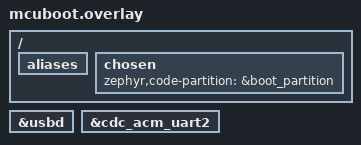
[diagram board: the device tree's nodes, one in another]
/*
 * Copyright (c) 2026 zlrs contributors
 *
 * SPDX-License-Identifier: Apache-2.0
 *
 * Devicetree overlay for the mcuboot image only (sysbuild picks up app/sysbuild/<image>.overlay).
 *
 * The application has data and management CDCs; the bootloader keeps two:
 *   - cdc_acm_uart0 = data port -> serial recovery (mcumgr frames; `zephyr,uart-mcumgr`
 *     points at it in the board dts)
 *   - cdc_acm_uart2 = console -> kernel log (disabled by default, enabled here)
 *   - cdc_acm_uart1 (management) is deleted in the bootloader
 * In upgrade mode the host then sees two MCUBOOT ports: recovery first, log second.
 *
 * This overlay also has to set `zephyr,code-partition = &boot_partition` itself: Zephyr only
 * falls back to MCUboot's own bootloader/mcuboot/boot/zephyr/app.overlay when there is *no*
 * DTC_OVERLAY_FILE, and that file holds this single line (the bootloader must link against the
 * mcuboot partition at 0x0, not slot0). Bring it along when providing your own overlay.
 */

/ {
	aliases {
		/delete-property/ zlrs-mgmt-cdc;
		/* zlrs-data-cdc points at the CDC used for recovery, keep it */
	};

	chosen {
		zephyr,code-partition = &boot_partition;
	};
};

&usbd {
	/delete-node/ cdc_acm_uart1;
};

&cdc_acm_uart2 {
	status = "okay";
};
